# GD32A503 register map
File version: 1.0
CPU: CM33 r0p4, little endian, MPU, FPU, 4 interrupt priority bits
Registers are 32-bit, read-write, reset 0x0 unless marked. A register's access mark holds for its fields unless they carry their own. Offsets are from the block's base; [hi:lo] are bit positions; {n}, {i} and the like mark numbered series; 'fields as' and 'values as' point back to an identical list.

## TRIGSEL — Trigger selection controller
Base 0x40018400
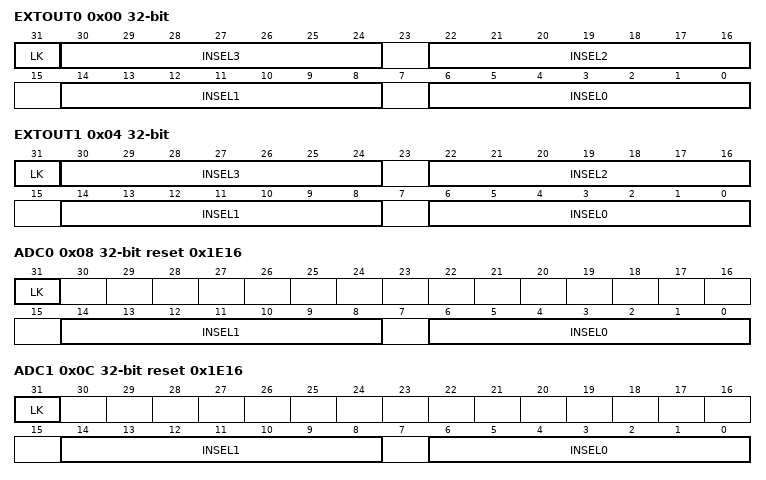
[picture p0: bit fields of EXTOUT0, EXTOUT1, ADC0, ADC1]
0x00 EXTOUT0 access per field — Trigger selection for EXTOUT0 register
  [31] LK ro — TRIGSEL register lock
  [8n+6:8n] INSEL{n} rw (n=0..3) — Trigger input source selection for output{n}
0x04 EXTOUT1 access per field — Trigger selection for EXTOUT1 register
  fields as EXTOUT0
0x08 ADC0 access per field reset 0x1E16 — Trigger selection for ADC0 register
  [31] LK ro — TRIGSEL register lock
  [14:8] INSEL1 rw — Trigger input source selection for output1
  [6:0] INSEL0 rw — Trigger input source selection for output0
0x0C ADC1 access per field reset 0x1E16 — Trigger selection for ADC1 register
  fields as ADC0
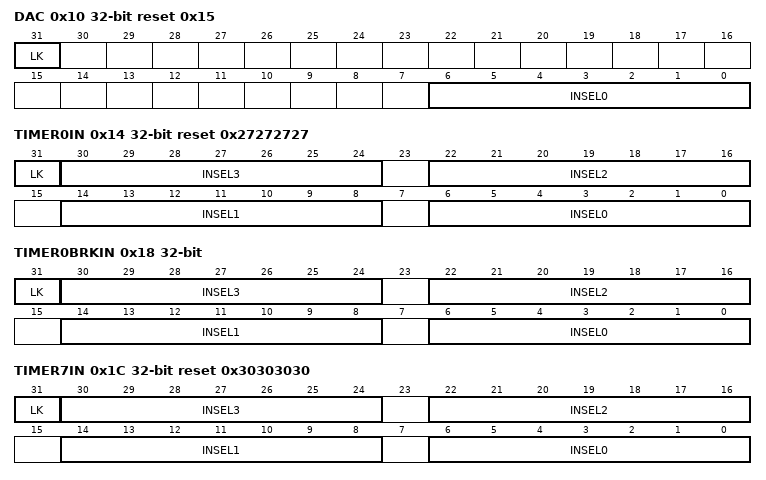
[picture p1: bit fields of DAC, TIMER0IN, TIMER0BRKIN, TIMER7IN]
0x10 DAC access per field reset 0x15 — Trigger selection for DAC register
  [31] LK ro — TRIGSEL register lock
  [6:0] INSEL0 rw — Trigger input source selection for output0
0x14 TIMER0IN access per field reset 0x27272727 — Trigger selection for TIMER0_ITI register
  fields as EXTOUT0
0x18 TIMER0BRKIN access per field — Trigger selection for TIMER0_BRKIN register
  fields as EXTOUT0
0x1C TIMER7IN access per field reset 0x30303030 — Trigger selection for TIMER7_ITI register
  fields as EXTOUT0
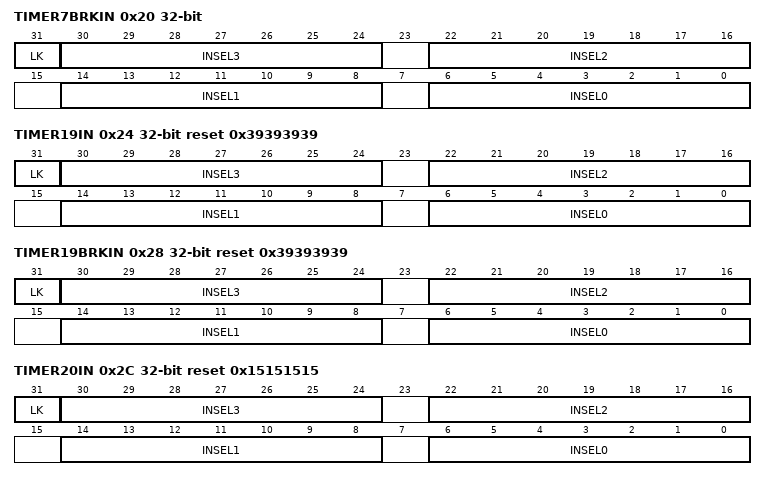
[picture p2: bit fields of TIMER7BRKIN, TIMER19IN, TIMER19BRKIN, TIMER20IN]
0x20 TIMER7BRKIN access per field — Trigger selection for TIMER7_BRKIN register
  fields as EXTOUT0
0x24 TIMER19IN access per field reset 0x39393939 — Trigger selection for TIMER19_ITI register
  fields as EXTOUT0
0x28 TIMER19BRKIN access per field reset 0x39393939 — Trigger selection for TIMER19_BRKIN register
  fields as EXTOUT0
0x2C TIMER20IN access per field reset 0x15151515 — Trigger selection for TIMER20_ITI register
  fields as EXTOUT0
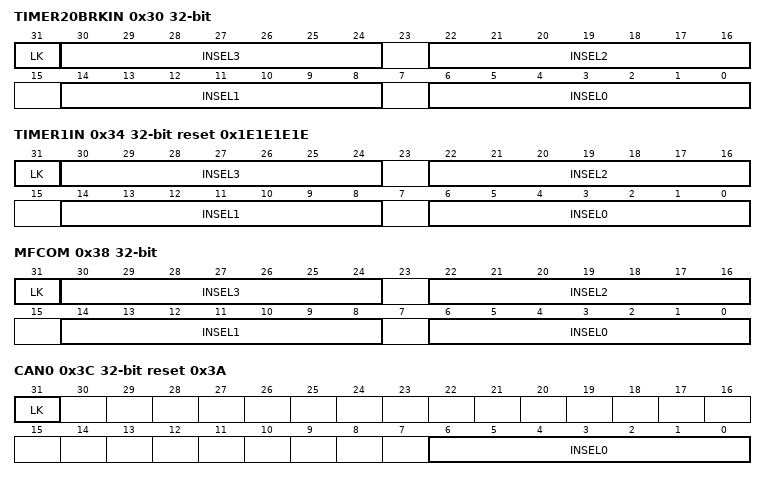
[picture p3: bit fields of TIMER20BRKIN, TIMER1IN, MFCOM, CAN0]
0x30 TIMER20BRKIN access per field — Trigger selection for TIMER20_BRKIN register
  fields as EXTOUT0
0x34 TIMER1IN access per field reset 0x1E1E1E1E — Trigger selection for TIMER1_ITI register
  fields as EXTOUT0
0x38 MFCOM access per field — Trigger selection for MFCOM register
  fields as EXTOUT0
0x3C CAN0 access per field reset 0x3A — Trigger selection for CAN0 register
  fields as DAC
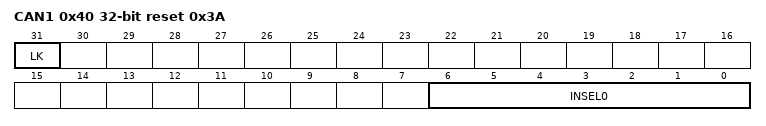
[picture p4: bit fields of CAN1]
0x40 CAN1 access per field reset 0x3A — Trigger selection for CAN1 register
  fields as DAC

## MFCOM — Multi-function communication Interface
Base 0x40038400
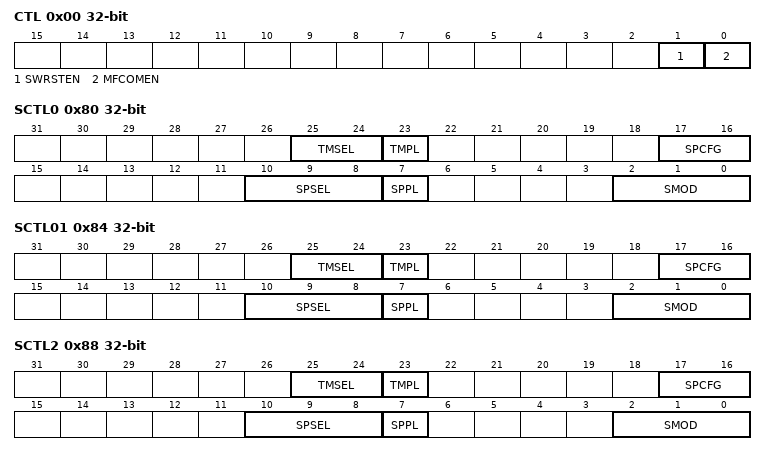
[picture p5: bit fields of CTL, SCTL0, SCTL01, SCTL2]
0x00 CTL — Control register
  [1] SWRSTEN — Software reset enable
  [0] MFCOMEN — MFCOM enable
0x04 PINDATA ro
  [7:0] PDATA — Input data of pins
0x08 SSTAT — Shifter status register
  [3:0] SSTAT — Shifter x status flag
0x0C SERR — Shifter error register
  [3:0] SERR — Shifter x error flags
0x10 TMSTAT — Timer status register
  [3:0] TMSTAT — Timer x status flags
0x18 SSIEN — Shifter status interrupt enable register
  [3:0] SSIEN — Shifter status interrupt enable
0x1C SEIEN — Shifter error interrupt enable register
  [3:0] SEIEN — Shifter error interrupt enable
0x20 TMSIEN — Timer status interrupt enable register
  [3:0] TMSIEN — Timer status interrupt enable
0x28 SSDMAEN — Shifter status DMA enable register
  [3:0] SSDMAEN — Shifter status DMA enable
0x80 SCTL0 — Shifter control x register
  [25:24] TMSEL — Timer select
  [23] TMPL — Timer polarity
  [17:16] SPCFG — Shifter pin configuration
  [10:8] SPSEL — Shifter pin select
  [7] SPPL — Shifter pin polarity
  [2:0] SMOD — Shifter mode
0x84 SCTL01 — Shifter control x register
  fields as SCTL0
0x88 SCTL2 — Shifter control x register
  fields as SCTL0
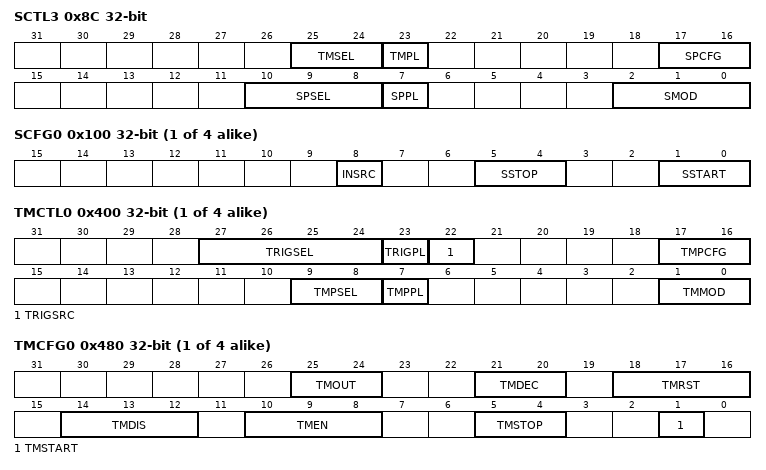
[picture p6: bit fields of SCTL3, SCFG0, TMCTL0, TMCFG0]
0x8C SCTL3 — Shifter control x register
  fields as SCTL0
{0x100+4i} SCFG{i} (i=0..3) — Shifter configuration x register
  [8] INSRC — Input source
  [5:4] SSTOP — Shifter stop bit
  [1:0] SSTART — Shifter start bit
{0x200+4i} SBUF{i} (i=0..3) — Shifter buffer x register
  [31:0] SBUF — Shift buffer
{0x280+4i} SBUFBIS{i} (i=0..3) — Shifter buffer x bit swapped register
  [31:0] SBUFBIS — Shift buffer bit swapped
{0x300+4i} SBUFBYS{i} (i=0..3) — Shifter buffer x byte swapped register
  [31:0] SBUFBYS — Shift buffer byte swapped
{0x380+4i} SBUFBBS{i} (i=0..3) — Shifter buffer x bit byte swapped register
  [31:0] SBUFBBS — Shift buffer bit byte swapped
{0x400+4i} TMCTL{i} (i=0..3) — Timer control x register
  [27:24] TRIGSEL — Trigger select
  [23] TRIGPL — Trigger polarity
  [22] TRIGSRC — Trigger source
  [17:16] TMPCFG — Timer pin configuration
  [9:8] TMPSEL — Timer Pin Select
  [7] TMPPL — Timer Pin Polarity
  [1:0] TMMOD — Timer Mode
{0x480+4i} TMCFG{i} (i=0..3) — Timer configuration x register
  [25:24] TMOUT — Timer output
  [21:20] TMDEC — Timer decrement
  [18:16] TMRST — Timer reset
  [14:12] TMDIS — Timer disable
  [10:8] TMEN — Timer enable
  [5:4] TMSTOP — Timer stop bit
  [1] TMSTART — Timer start bit
{0x500+4i} TMCMP{i} (i=0..3) — Timer compare x register
  [15:0] TMCVALUE — Timer compare value
